VERSION "sdv-integration-lab-v1"
NS_ :

BS_:
BU_: Vehicle Gateway
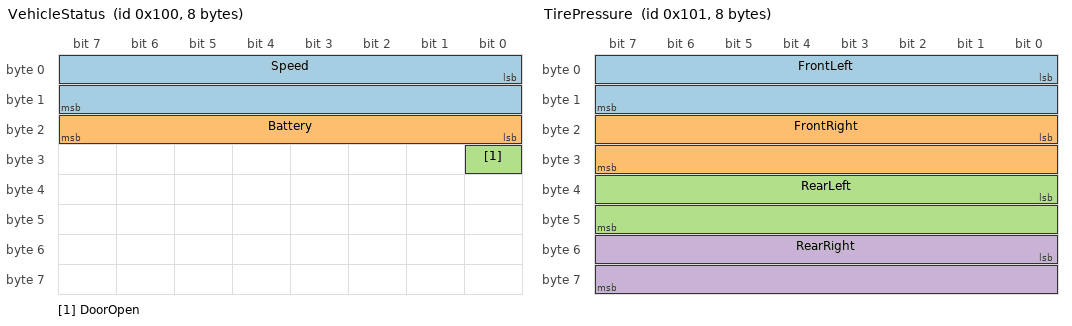
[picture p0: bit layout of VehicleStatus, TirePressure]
BO_ 256 VehicleStatus: 8 Vehicle
 SG_ Speed : 0|16@1+ (0.01,0) [0|250] "km/h" Gateway
 SG_ Battery : 16|8@1+ (1,0) [0|100] "%" Gateway
 SG_ DoorOpen : 24|1@1+ (1,0) [0|1] "" Gateway
BO_ 257 TirePressure: 8 Vehicle
 SG_ FrontLeft : 0|16@1+ (1,0) [0|1000] "kPa" Gateway
 SG_ FrontRight : 16|16@1+ (1,0) [0|1000] "kPa" Gateway
 SG_ RearLeft : 32|16@1+ (1,0) [0|1000] "kPa" Gateway
 SG_ RearRight : 48|16@1+ (1,0) [0|1000] "kPa" Gateway
